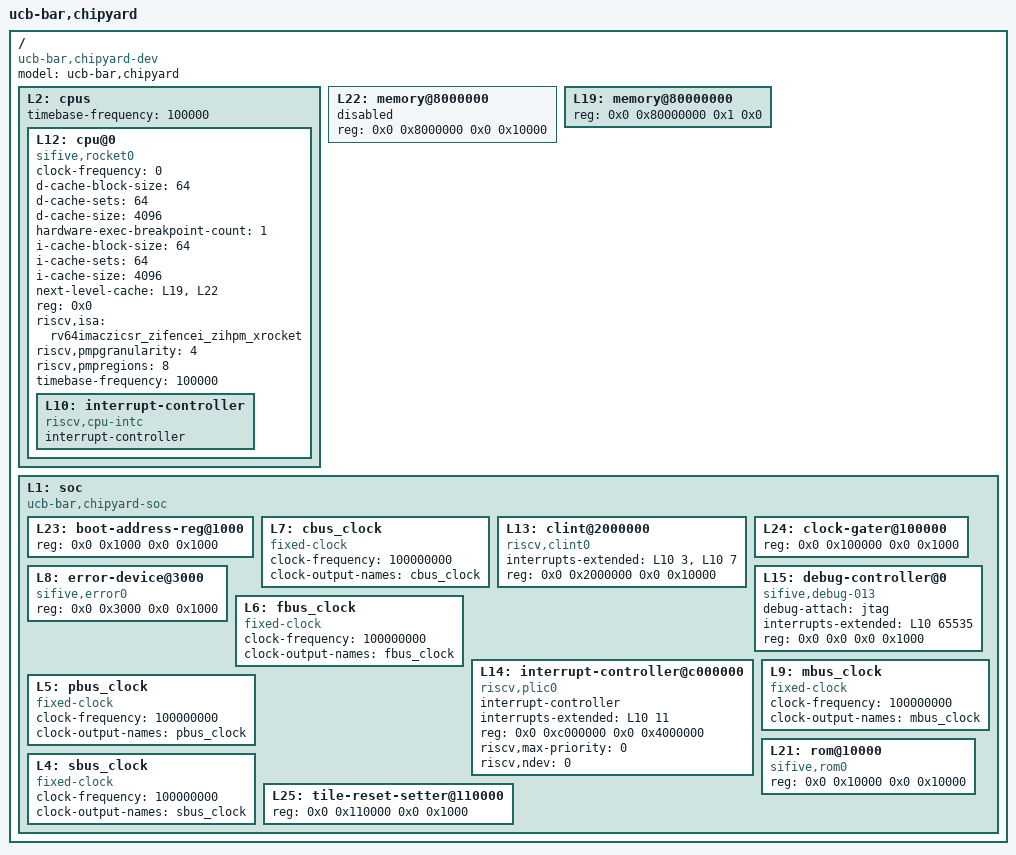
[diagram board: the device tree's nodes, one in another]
/dts-v1/;

/ {
	#address-cells = <2>;
	#size-cells = <2>;
	compatible = "ucb-bar,chipyard-dev";
	model = "ucb-bar,chipyard";
	L2: cpus {
		#address-cells = <1>;
		#size-cells = <0>;
		timebase-frequency = <100000>;
		L12: cpu@0 {
			clock-frequency = <0>;
			compatible = "sifive,rocket0", "riscv";
			d-cache-block-size = <64>;
			d-cache-sets = <64>;
			d-cache-size = <4096>;
			device_type = "cpu";
			hardware-exec-breakpoint-count = <1>;
			i-cache-block-size = <64>;
			i-cache-sets = <64>;
			i-cache-size = <4096>;
			next-level-cache = <&L19 &L22>;
			reg = <0x0>;
			riscv,isa = "rv64imaczicsr_zifencei_zihpm_xrocket";
			riscv,pmpgranularity = <4>;
			riscv,pmpregions = <8>;
			status = "okay";
			timebase-frequency = <100000>;
			L10: interrupt-controller {
				#interrupt-cells = <1>;
				compatible = "riscv,cpu-intc";
				interrupt-controller;
			};
		};
	};
	L22: memory@8000000 {
		device_type = "memory";
		reg = <0x0 0x8000000 0x0 0x10000>;
		status = "disabled";
	};
	L19: memory@80000000 {
		device_type = "memory";
		reg = <0x0 0x80000000 0x1 0x0>;
	};
	L1: soc {
		#address-cells = <2>;
		#size-cells = <2>;
		compatible = "ucb-bar,chipyard-soc", "simple-bus";
		ranges;
		L23: boot-address-reg@1000 {
			reg = <0x0 0x1000 0x0 0x1000>;
			reg-names = "control";
		};
		L7: cbus_clock {
			#clock-cells = <0>;
			clock-frequency = <100000000>;
			clock-output-names = "cbus_clock";
			compatible = "fixed-clock";
		};
		L13: clint@2000000 {
			compatible = "riscv,clint0";
			interrupts-extended = <&L10 3 &L10 7>;
			reg = <0x0 0x2000000 0x0 0x10000>;
			reg-names = "control";
		};
		L24: clock-gater@100000 {
			reg = <0x0 0x100000 0x0 0x1000>;
			reg-names = "control";
		};
		L15: debug-controller@0 {
			compatible = "sifive,debug-013", "riscv,debug-013";
			debug-attach = "jtag";
			interrupts-extended = <&L10 65535>;
			reg = <0x0 0x0 0x0 0x1000>;
			reg-names = "control";
		};
		L8: error-device@3000 {
			compatible = "sifive,error0";
			reg = <0x0 0x3000 0x0 0x1000>;
		};
		L6: fbus_clock {
			#clock-cells = <0>;
			clock-frequency = <100000000>;
			clock-output-names = "fbus_clock";
			compatible = "fixed-clock";
		};
		L14: interrupt-controller@c000000 {
			#interrupt-cells = <1>;
			compatible = "riscv,plic0";
			interrupt-controller;
			interrupts-extended = <&L10 11>;
			reg = <0x0 0xc000000 0x0 0x4000000>;
			reg-names = "control";
			riscv,max-priority = <0>;
			riscv,ndev = <0>;
		};
		L9: mbus_clock {
			#clock-cells = <0>;
			clock-frequency = <100000000>;
			clock-output-names = "mbus_clock";
			compatible = "fixed-clock";
		};
		L5: pbus_clock {
			#clock-cells = <0>;
			clock-frequency = <100000000>;
			clock-output-names = "pbus_clock";
			compatible = "fixed-clock";
		};
		L21: rom@10000 {
			compatible = "sifive,rom0";
			reg = <0x0 0x10000 0x0 0x10000>;
			reg-names = "mem";
		};
		L4: sbus_clock {
			#clock-cells = <0>;
			clock-frequency = <100000000>;
			clock-output-names = "sbus_clock";
			compatible = "fixed-clock";
		};
		L25: tile-reset-setter@110000 {
			reg = <0x0 0x110000 0x0 0x1000>;
			reg-names = "control";
		};
	};
};
